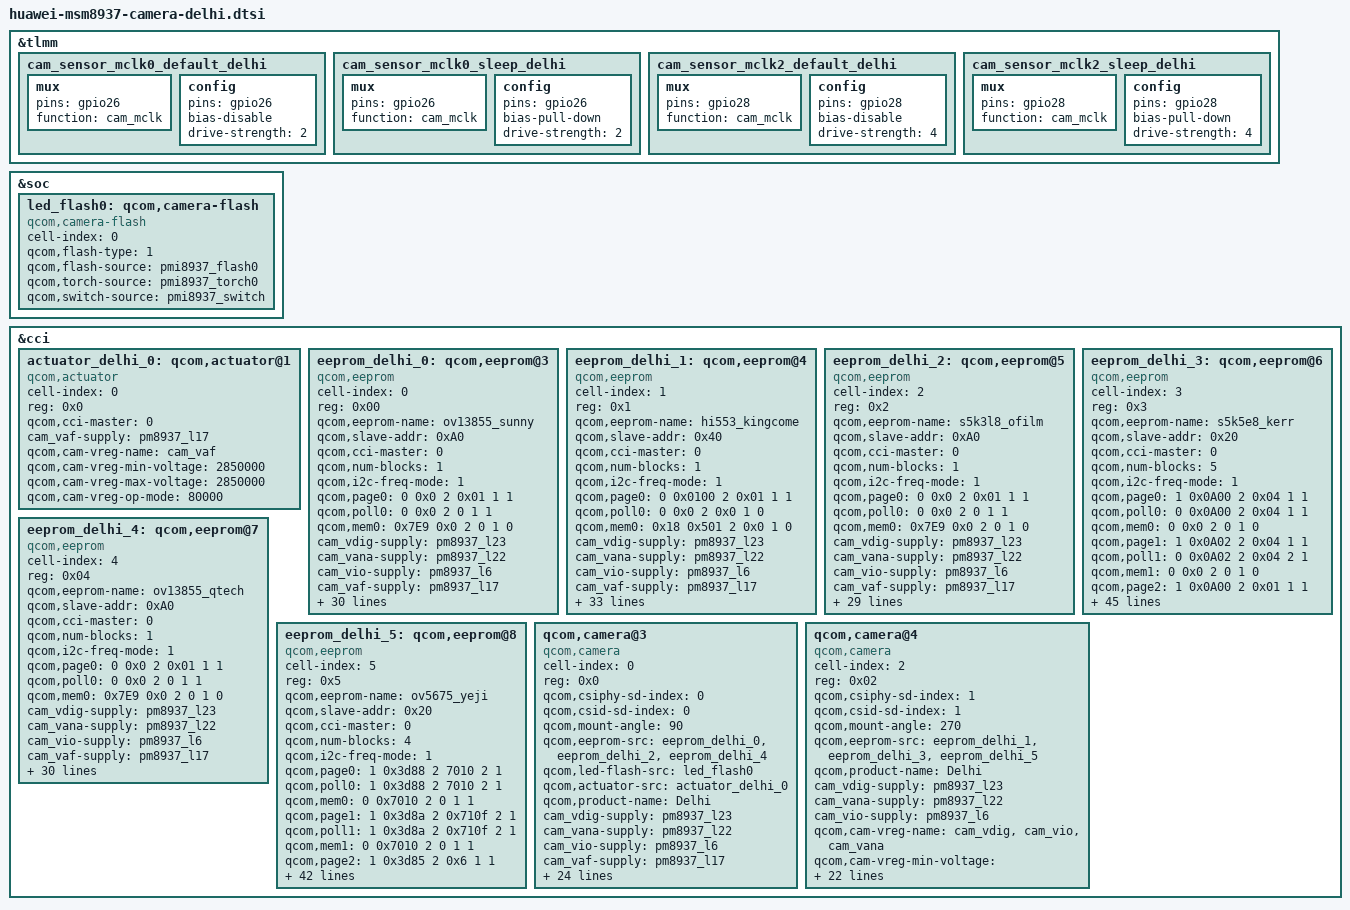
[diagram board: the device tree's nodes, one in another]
/*
 * Copyright (c) 2015-2016, The Linux Foundation. All rights reserved.
 *
 * This program is free software; you can redistribute it and/or modify
 * it under the terms of the GNU General Public License version 2 and
 * only version 2 as published by the Free Software Foundation.
 *
 * This program is distributed in the hope that it will be useful,
 * but WITHOUT ANY WARRANTY; without even the implied warranty of
 * MERCHANTABILITY or FITNESS FOR A PARTICULAR PURPOSE.  See the
 * GNU General Public License for more details.
 */
&tlmm {
	cam_sensor_mclk0_default_delhi: cam_sensor_mclk0_default_delhi {
		/* MCLK0 */
		mux {
			/* CLK, DATA */
			pins = "gpio26";
			function = "cam_mclk";
		};

		config {
			pins = "gpio26";
			bias-disable; /* No PULL */
			drive-strength = <2>; /* 2 MA */
		};
	};

	cam_sensor_mclk0_sleep_delhi: cam_sensor_mclk0_sleep_delhi {
		/* MCLK0 */
		mux {
			/* CLK, DATA */
			pins = "gpio26";
			function = "cam_mclk";
		};

		config {
			pins = "gpio26";
			bias-pull-down; /* PULL DOWN */
			drive-strength = <2>; /* 2 MA */
		};
	};

	cam_sensor_mclk2_default_delhi: cam_sensor_mclk2_default_delhi {
		/* CAMIF_MCLK2 */
		mux {
			/* CLK, DATA */
			pins = "gpio28";
			function = "cam_mclk";
		};

		config {
			pins = "gpio28";
			bias-disable; /* No PULL */
			drive-strength = <4>; /* 4 MA */
		};
	};

	cam_sensor_mclk2_sleep_delhi: cam_sensor_mclk2_sleep_delhi {
		/* CAMIF_MCLK2 */
		mux {
			/* CLK, DATA */
			pins = "gpio28";
			function = "cam_mclk";
		};

		config {
			pins = "gpio28";
			bias-pull-down; /* PULL DOWN */
			drive-strength = <4>; /* 4 MA */
		};
	};

};
&soc {
	/delete-node/ qcom,camera-flash;
        led_flash0: qcom,camera-flash {
                cell-index = <0>;
                compatible = "qcom,camera-flash";
                qcom,flash-type = <1>;
                qcom,flash-source = <&pmi8937_flash0>;
                qcom,torch-source = <&pmi8937_torch0>;
                qcom,switch-source = <&pmi8937_switch>;
        };
};

&cci {
    /*delete qcom default node in msm8937-camera-sensor-qrd.dtsi*/
	/delete-node/ qcom,actuator@0;
	/delete-node/ qcom,eeprom@0;
	/delete-node/ qcom,eeprom@2;
	/delete-node/ qcom,camera@0;
	/delete-node/ qcom,camera@2;
	actuator_delhi_0: qcom,actuator@1 {
		cell-index = <0>;
		reg = <0x0>;
		compatible = "qcom,actuator";
		qcom,cci-master = <0>;
		cam_vaf-supply = <&pm8937_l17>;
		qcom,cam-vreg-name = "cam_vaf";
		qcom,cam-vreg-min-voltage = <2850000>;
		qcom,cam-vreg-max-voltage = <2850000>;
		qcom,cam-vreg-op-mode = <80000>;
	};

	eeprom_delhi_0: qcom,eeprom@3 {
		cell-index = <0>;
		reg = <0x00>;
		qcom,eeprom-name = "ov13855_sunny";
		compatible = "qcom,eeprom";
		qcom,slave-addr = <0xA0>;
		qcom,cci-master = <0>;
		qcom,num-blocks = <1>;
		qcom,i2c-freq-mode = <1>;

		qcom,page0 = <0 0x0 2 0x01 1 1>;
		qcom,poll0 = <0 0x0 2 0 1 1>;
		qcom,mem0 = <0x7E9 0x0 2 0 1 0>;

		cam_vdig-supply = <&pm8937_l23>;
		cam_vana-supply = <&pm8937_l22>;
		cam_vio-supply = <&pm8937_l6>;
		cam_vaf-supply = <&pm8937_l17>;
		qcom,cam-vreg-name = "cam_vdig", "cam_vio", "cam_vana",
							"cam_vaf";
		qcom,cam-vreg-min-voltage = <1200000 1800000 3000000 2850000>;
		qcom,cam-vreg-max-voltage = <1200000 1800000 3000000 2850000>;
		qcom,cam-vreg-op-mode = <200000 80000 80000 100000>;
		pinctrl-names = "cam_default", "cam_suspend";
		pinctrl-0 = <&cam_sensor_mclk0_default_delhi &cam_sensor_rear_default>;
		pinctrl-1 = <&cam_sensor_mclk0_sleep_delhi &cam_sensor_rear_sleep>;
		gpios = <&tlmm 26 0>,
			<&tlmm 35 0>;
		qcom,gpio-reset = <1>;
		qcom,gpio-req-tbl-num = <0 1>;
		qcom,gpio-req-tbl-flags = <1 0>;
		qcom,gpio-req-tbl-label = "CAMIF_MCLK0",
			"CAM_RESET0";
		qcom,cam-power-seq-type = "sensor_gpio", "sensor_vreg", "sensor_vreg", "sensor_vreg", "sensor_vreg",
				"sensor_gpio", "sensor_clk";
		qcom,cam-power-seq-val = "sensor_gpio_reset", "cam_vio", "cam_vana", "cam_vdig", "cam_vaf",
				"sensor_gpio_reset", "sensor_cam_mclk";
		qcom,cam-power-seq-cfg-val = <0 0 0 0 0 1 19200000>;
		qcom,cam-power-seq-delay =   <1 0 0 0 5 5 1>;
		status = "ok";
		clocks = <&clock_gcc clk_mclk0_clk_src>,
				<&clock_gcc clk_gcc_camss_mclk0_clk>;
		clock-names = "cam_src_clk", "cam_clk";
		qcom,clock-rates = <19200000 0>;
	};

	eeprom_delhi_1: qcom,eeprom@4 {
		cell-index = <1>;
		reg = <0x1>;
		qcom,eeprom-name = "hi553_kingcome";
		compatible = "qcom,eeprom";
		qcom,slave-addr = <0x40>;
		qcom,cci-master = <0>;
		qcom,num-blocks = <1>;
		qcom,i2c-freq-mode = <1>;

		qcom,page0 = <0 0x0100 2 0x01 1 1>;
		qcom,poll0 = <0 0x0 2 0x0 1 0>;
		qcom,mem0 = <0x18 0x501 2 0x0 1 0>; 

		cam_vdig-supply = <&pm8937_l23>;
		cam_vana-supply = <&pm8937_l22>;
		cam_vio-supply = <&pm8937_l6>;
		cam_vaf-supply = <&pm8937_l17>;
		qcom,cam-vreg-name = "cam_vdig", "cam_vio", "cam_vana";
		qcom,cam-vreg-min-voltage = <1200000 1800000 3000000>;
		qcom,cam-vreg-max-voltage = <1200000 1800000 3000000>;
		qcom,cam-vreg-op-mode = <105000 80000 80000>;
		qcom,gpio-no-mux = <0>;
		pinctrl-names = "cam_default", "cam_suspend";
		pinctrl-0 = <&cam_sensor_mclk2_default_delhi
			&cam_sensor_front1_default>;
		pinctrl-1 = <&cam_sensor_mclk2_sleep_delhi &cam_sensor_front1_sleep>;
		gpios = <&tlmm 28 0>,
			<&tlmm 40 0>,
			<&tlmm 39 0>;
		qcom,gpio-reset = <1>;
		qcom,gpio-standby = <2>;
		qcom,gpio-req-tbl-num = <0 1 2>;
		qcom,gpio-req-tbl-flags = <1 0 0>;
		qcom,gpio-req-tbl-label = "CAMIF_MCLK2",
					  "CAM_RESET2",
					  "CAM_STANDBY2";
		qcom,cam-power-seq-type = "sensor_vreg", "sensor_vreg", "sensor_vreg", "sensor_clk", "sensor_gpio",
		"sensor_gpio", "sensor_gpio", "sensor_gpio";
		qcom,cam-power-seq-val = "cam_vio", "cam_vana", "cam_vdig",  "sensor_cam_mclk", "sensor_gpio_standby",
		"sensor_gpio_standby", "sensor_gpio_reset", "sensor_gpio_reset";
		qcom,cam-power-seq-cfg-val = <0 0 0 24000000 0 1 0 1>;
		qcom,cam-power-seq-delay = <0 0 0 10 1 1 1 5>;
		status = "ok";
		clocks = <&clock_gcc clk_mclk2_clk_src>,
			<&clock_gcc clk_gcc_camss_mclk2_clk>;
		clock-names = "cam_src_clk", "cam_clk";
		qcom,clock-rates = <24000000 0>;
	};

	eeprom_delhi_2: qcom,eeprom@5 {
		cell-index = <2>;
		reg = <0x2>;
		qcom,eeprom-name = "s5k3l8_ofilm";
		compatible = "qcom,eeprom";
		qcom,slave-addr = <0xA0>;
		qcom,cci-master = <0>;
		qcom,num-blocks = <1>;
		qcom,i2c-freq-mode = <1>;

		qcom,page0 = <0 0x0 2 0x01 1 1>;
		qcom,poll0 = <0 0x0 2 0 1 1>;
		qcom,mem0 = <0x7E9 0x0 2 0 1 0>;

		cam_vdig-supply = <&pm8937_l23>;
		cam_vana-supply = <&pm8937_l22>;
		cam_vio-supply = <&pm8937_l6>;
		cam_vaf-supply = <&pm8937_l17>;
		qcom,cam-vreg-name = "cam_vdig", "cam_vio", "cam_vana",
							"cam_vaf";
		qcom,cam-vreg-min-voltage = <1200000 1800000 3000000 2850000>;
		qcom,cam-vreg-max-voltage = <1200000 1800000 3000000 2850000>;
		qcom,cam-vreg-op-mode = <200000 80000 80000 100000>;
		pinctrl-names = "cam_default", "cam_suspend";
		pinctrl-0 = <&cam_sensor_mclk0_default_delhi &cam_sensor_rear_default>;
		pinctrl-1 = <&cam_sensor_mclk0_sleep_delhi &cam_sensor_rear_sleep>;
		gpios = <&tlmm 26 0>,
			<&tlmm 35 0>;
		qcom,gpio-reset = <1>;
		qcom,gpio-req-tbl-num = <0 1>;
		qcom,gpio-req-tbl-flags = <1 0>;
		qcom,gpio-req-tbl-label = "CAMIF_MCLK0",
			"CAM_RESET0";
		qcom,cam-power-seq-type = "sensor_gpio", "sensor_vreg", "sensor_vreg", "sensor_vreg",
			"sensor_clk", "sensor_gpio";
		qcom,cam-power-seq-val = "sensor_gpio_reset", "cam_vana", "cam_vio", "cam_vdig",
			"sensor_cam_mclk", "sensor_gpio_reset";
		qcom,cam-power-seq-cfg-val = <0 0 0 0 19200000 1>;
		qcom,cam-power-seq-delay = <1 0 0 0 1 1>;
		status = "ok";
		clocks = <&clock_gcc clk_mclk0_clk_src>,
				<&clock_gcc clk_gcc_camss_mclk0_clk>;
		clock-names = "cam_src_clk", "cam_clk";
		qcom,clock-rates = <19200000 0>;
	};

	eeprom_delhi_3: qcom,eeprom@6 {
		cell-index = <3>;
		reg = <0x3>;
		qcom,eeprom-name = "s5k5e8_kerr";
		compatible = "qcom,eeprom";
		qcom,slave-addr = <0x20>;
		qcom,cci-master = <0>;
		qcom,num-blocks = <5>;
		qcom,i2c-freq-mode = <1>;

		//make initial state
		qcom,page0 = <1 0x0A00 2 0x04 1 1>;
		qcom,poll0 = <0 0x0A00 2 0x04 1 1>;
		qcom,mem0 = <0 0x0 2 0 1 0>;
		//set the PAGE4 of OTP and read data
		qcom,page1 = <1 0x0A02 2 0x04 1 1>;
		qcom,poll1 = <0 0x0A02 2 0x04 2 1>;
		qcom,mem1 = <0 0x0 2 0 1 0>;
		//set read mode of NVM controller interface1
		qcom,page2 = <1 0x0A00 2 0x01 1 1>;
		qcom,poll2 = <0 0x0A00 2 0x01 1 1>;
		qcom,mem2 = <24 0x0A04 2 0 1 1>;
		//make initial state
		qcom,page3 = <1 0x0A00 2 0x04 1 1>;
		qcom,poll3 = <0 0x0A00 2 0x04 1 1>;
		qcom,mem3 = <0 0x0 2 0 1 0>;
		//disable NVM controller
		qcom,page4 = <1 0x0A00 2 0x00 1 1>;
		qcom,poll4 =   <0 0x0A00 2 0x00 1 0>;
		qcom,mem4 = <0 0x0 2 0 1 0>;

		cam_vdig-supply = <&pm8937_l23>;
		cam_vana-supply = <&pm8937_l22>;
		cam_vio-supply = <&pm8937_l6>;
		cam_vaf-supply = <&pm8937_l17>;
		qcom,cam-vreg-name = "cam_vdig", "cam_vio", "cam_vana";
		qcom,cam-vreg-min-voltage = <1200000 1800000 3000000>;
		qcom,cam-vreg-max-voltage = <1200000 1800000 3000000>;
		qcom,cam-vreg-op-mode = <105000 80000 80000>;
		qcom,gpio-no-mux = <0>;
		pinctrl-names = "cam_default", "cam_suspend";
		pinctrl-0 = <&cam_sensor_mclk2_default_delhi
			&cam_sensor_front1_default>;
		pinctrl-1 = <&cam_sensor_mclk2_sleep_delhi &cam_sensor_front1_sleep>;
		gpios = <&tlmm 28 0>,
			<&tlmm 40 0>,
			<&tlmm 39 0>;
		qcom,gpio-reset = <1>;
		qcom,gpio-standby = <2>;
		qcom,gpio-req-tbl-num = <0 1 2>;
		qcom,gpio-req-tbl-flags = <1 0 0>;
		qcom,gpio-req-tbl-label = "CAMIF_MCLK2",
					  "CAM_RESET2",
					  "CAM_STANDBY2";
		qcom,cam-power-seq-type = "sensor_gpio", "sensor_gpio", "sensor_vreg", "sensor_vreg",
			"sensor_vreg", "sensor_clk", "sensor_gpio", "sensor_gpio";
		qcom,cam-power-seq-val = "sensor_gpio_reset", "sensor_gpio_standby", "cam_vana", "cam_vdig", "cam_vio",
			"sensor_cam_mclk", "sensor_gpio_reset", "sensor_gpio_standby";
		qcom,cam-power-seq-cfg-val = <0 0 1 1 1 24000000 1 1>;
		qcom,cam-power-seq-delay = <1 1 5 5 5 1 10 10>;
		status = "ok";
		clocks = <&clock_gcc clk_mclk2_clk_src>,
			<&clock_gcc clk_gcc_camss_mclk2_clk>;
		clock-names = "cam_src_clk", "cam_clk";
		qcom,clock-rates = <24000000 0>;
	};

	eeprom_delhi_4: qcom,eeprom@7 {
		cell-index = <4>;
		reg = <0x04>;
		qcom,eeprom-name = "ov13855_qtech";
		compatible = "qcom,eeprom";
		qcom,slave-addr = <0xA0>;
		qcom,cci-master = <0>;
		qcom,num-blocks = <1>;
		qcom,i2c-freq-mode = <1>;

		qcom,page0 = <0 0x0 2 0x01 1 1>;
		qcom,poll0 = <0 0x0 2 0 1 1>;
		qcom,mem0 = <0x7E9 0x0 2 0 1 0>;

		cam_vdig-supply = <&pm8937_l23>;
		cam_vana-supply = <&pm8937_l22>;
		cam_vio-supply = <&pm8937_l6>;
		cam_vaf-supply = <&pm8937_l17>;
		qcom,cam-vreg-name = "cam_vdig", "cam_vio", "cam_vana",
							"cam_vaf";
		qcom,cam-vreg-min-voltage = <1200000 1800000 3000000 2850000>;
		qcom,cam-vreg-max-voltage = <1200000 1800000 3000000 2850000>;
		qcom,cam-vreg-op-mode = <200000 80000 80000 100000>;
		pinctrl-names = "cam_default", "cam_suspend";
		pinctrl-0 = <&cam_sensor_mclk0_default_delhi &cam_sensor_rear_default>;
		pinctrl-1 = <&cam_sensor_mclk0_sleep_delhi &cam_sensor_rear_sleep>;
		gpios = <&tlmm 26 0>,
			<&tlmm 35 0>;
		qcom,gpio-reset = <1>;
		qcom,gpio-req-tbl-num = <0 1>;
		qcom,gpio-req-tbl-flags = <1 0>;
		qcom,gpio-req-tbl-label = "CAMIF_MCLK0",
			"CAM_RESET0";
		qcom,cam-power-seq-type = "sensor_gpio", "sensor_vreg", "sensor_vreg", "sensor_vreg", "sensor_vreg",
				"sensor_gpio", "sensor_clk";
		qcom,cam-power-seq-val = "sensor_gpio_reset", "cam_vio", "cam_vana", "cam_vdig", "cam_vaf",
				"sensor_gpio_reset", "sensor_cam_mclk";
		qcom,cam-power-seq-cfg-val = <0 0 0 0 0 1 19200000>;
		qcom,cam-power-seq-delay =   <1 0 0 0 5 5 1>;
		status = "ok";
		clocks = <&clock_gcc clk_mclk0_clk_src>,
				<&clock_gcc clk_gcc_camss_mclk0_clk>;
		clock-names = "cam_src_clk", "cam_clk";
		qcom,clock-rates = <19200000 0>;
	};

	eeprom_delhi_5: qcom,eeprom@8 {
		cell-index = <5>;
		reg = <0x5>;
		qcom,eeprom-name = "ov5675_yeji";
		compatible = "qcom,eeprom";
		qcom,slave-addr = <0x20>;
		qcom,cci-master = <0>;
		qcom,num-blocks = <4>;
		qcom,i2c-freq-mode = <1>;

		qcom,page0 = <1 0x3d88 2 7010 2 1>;
		qcom,poll0 = <1 0x3d88 2 7010 2 1>;
		qcom,mem0 = <0 0x7010 2 0 1 1>;
		qcom,page1 = <1 0x3d8a 2 0x710f 2 1>;
		qcom,poll1 = <1 0x3d8a 2 0x710f 2 1>;
		qcom,mem1 = <0 0x7010 2 0 1 1>;
		qcom,page2 = <1 0x3d85 2 0x6 1 1>;
		qcom,poll2 = <1 0x3d85 2 0x6 1 1>;
		qcom,mem2 = <0 0x7010 2 0 1 1>;
		qcom,page3 = <1 0x0100 2 0x1 1 1>;
		qcom,poll3 = <0 0x0100 2 0x1 1 1>;
		qcom,mem3 = <0x18 0x7010 2 0 1 1>;

		cam_vdig-supply = <&pm8937_l23>;
		cam_vana-supply = <&pm8937_l22>;
		cam_vio-supply = <&pm8937_l6>;
		cam_vaf-supply = <&pm8937_l17>;
		qcom,cam-vreg-name = "cam_vdig", "cam_vio", "cam_vana";
		qcom,cam-vreg-min-voltage = <1200000 1800000 3000000>;
		qcom,cam-vreg-max-voltage = <1200000 1800000 3000000>;
		qcom,cam-vreg-op-mode = <105000 80000 80000>;
		qcom,gpio-no-mux = <0>;
		pinctrl-names = "cam_default", "cam_suspend";
		pinctrl-0 = <&cam_sensor_mclk2_default_delhi
			&cam_sensor_front1_default>;
		pinctrl-1 = <&cam_sensor_mclk2_sleep_delhi &cam_sensor_front1_sleep>;
		gpios = <&tlmm 28 0>,
			<&tlmm 40 0>,
			<&tlmm 39 0>;
		qcom,gpio-reset = <1>;
		qcom,gpio-standby = <2>;
		qcom,gpio-req-tbl-num = <0 1 2>;
		qcom,gpio-req-tbl-flags = <1 0 0>;
		qcom,gpio-req-tbl-label = "CAMIF_MCLK2",
					  "CAM_RESET2",
					  "CAM_STANDBY2";
		qcom,cam-power-seq-type = "sensor_vreg", "sensor_vreg", "sensor_vreg", "sensor_gpio", "sensor_gpio",
		"sensor_gpio", "sensor_gpio", "sensor_clk";
		qcom,cam-power-seq-val = "cam_vio", "cam_vana", "cam_vdig", "sensor_gpio_standby", "sensor_gpio_standby",
		"sensor_gpio_reset", "sensor_gpio_reset", "sensor_cam_mclk";
		qcom,cam-power-seq-cfg-val = <0 0 0 0 1 0 1 24000000>;
		qcom,cam-power-seq-delay = <1 1 5 1 5 5 10 10>;
		status = "ok";
		clocks = <&clock_gcc clk_mclk2_clk_src>,
			<&clock_gcc clk_gcc_camss_mclk2_clk>;
		clock-names = "cam_src_clk", "cam_clk";
		qcom,clock-rates = <24000000 0>;
	};

	qcom,camera@3 {
		cell-index = <0>;
		compatible = "qcom,camera";
		reg = <0x0>;
		qcom,csiphy-sd-index = <0>;
		qcom,csid-sd-index = <0>;
		qcom,mount-angle = <90>;
		qcom,eeprom-src = <&eeprom_delhi_0 &eeprom_delhi_2 &eeprom_delhi_4>;
		qcom,led-flash-src = <&led_flash0>;
		qcom,actuator-src = <&actuator_delhi_0>;
		qcom,product-name = "Delhi";
		cam_vdig-supply = <&pm8937_l23>;
		cam_vana-supply = <&pm8937_l22>;
		cam_vio-supply = <&pm8937_l6>;
		cam_vaf-supply = <&pm8937_l17>;
		qcom,cam-vreg-name = "cam_vdig", "cam_vio", "cam_vana",
							"cam_vaf";
		qcom,cam-vreg-min-voltage = <1200000 1800000 3000000 2850000>;
		qcom,cam-vreg-max-voltage = <1200000 1800000 3000000 2850000>;
		qcom,cam-vreg-op-mode = <105000 80000 80000 100000>;
		pinctrl-names = "cam_default", "cam_suspend";
		pinctrl-0 = <&cam_sensor_mclk0_default_delhi
				&cam_sensor_rear_default>;
		pinctrl-1 = <&cam_sensor_mclk0_sleep_delhi &cam_sensor_rear_sleep>;
		gpios = <&tlmm 26 0>,
			<&tlmm 35 0>;
		qcom,gpio-reset = <1>;
		qcom,gpio-req-tbl-num = <0 1>;
		qcom,gpio-req-tbl-flags = <1 0>;
		qcom,gpio-req-tbl-label = "CAMIF_MCLK0",
			"CAM_RESET0";
		qcom,sensor-position = <0>;
		qcom,sensor-mode = <0>;
		qcom,cci-master = <0>;
		status = "ok";
		clocks = <&clock_gcc clk_mclk0_clk_src>,
				<&clock_gcc clk_gcc_camss_mclk0_clk>;
		clock-names = "cam_src_clk", "cam_clk";
		qcom,clock-rates = <19200000 0>;
	};

	qcom,camera@4 {
		cell-index = <2>;
		compatible = "qcom,camera";
		reg = <0x02>;
		qcom,csiphy-sd-index = <1>;
		qcom,csid-sd-index = <1>;
		qcom,mount-angle = <270>;
		qcom,eeprom-src = <&eeprom_delhi_1 &eeprom_delhi_3 &eeprom_delhi_5>;
		qcom,product-name = "Delhi";
		cam_vdig-supply = <&pm8937_l23>;
		cam_vana-supply = <&pm8937_l22>;
		cam_vio-supply = <&pm8937_l6>;
		qcom,cam-vreg-name = "cam_vdig", "cam_vio", "cam_vana";
		qcom,cam-vreg-min-voltage = <1200000 1800000 3000000>;
		qcom,cam-vreg-max-voltage = <1200000 1800000 3000000>;
		qcom,cam-vreg-op-mode = <105000 80000 80000>;
		qcom,gpio-no-mux = <0>;
		pinctrl-names = "cam_default", "cam_suspend";
		pinctrl-0 = <&cam_sensor_mclk2_default_delhi &cam_sensor_front1_default>;
		pinctrl-1 = <&cam_sensor_mclk2_sleep_delhi &cam_sensor_front1_sleep>;
		gpios = <&tlmm 28 0>,
			<&tlmm 40 0>,
			<&tlmm 39 0>;
		qcom,gpio-reset = <1>;
		qcom,gpio-standby = <2>;
		qcom,gpio-req-tbl-num = <0 1 2>;
		qcom,gpio-req-tbl-flags = <1 0 0>;
		qcom,gpio-req-tbl-label = "CAMIF_MCLK2",
					  "CAM_RESET2",
					  "CAM_STANDBY2";
		qcom,sensor-position = <1>;
		qcom,sensor-mode = <0>;
		qcom,cci-master = <0>;
		status = "ok";
		clocks = <&clock_gcc clk_mclk2_clk_src>,
			<&clock_gcc clk_gcc_camss_mclk2_clk>;
		clock-names = "cam_src_clk", "cam_clk";
		qcom,clock-rates = <24000000 0>;
	};
};
